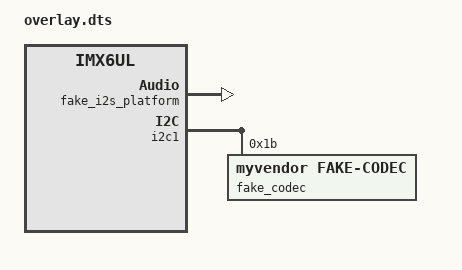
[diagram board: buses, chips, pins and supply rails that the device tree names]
// SPDX-License-Identifier: GPL-2.0
/*
 * Device Tree Overlay for Fake Audio Driver
 * Reference implementation showing required nodes
 */

/dts-v1/;
/plugin/;

/ {
	compatible = "fsl,imx6ul-14x14-evk", "fsl,imx6ul";

	fragment@0 {
		target-path = "/soc";
		__overlay__ {
			fake_cpu_dai: fake_cpu_dai {
				compatible = "myvendor,fake-cpu-dai";
				#sound-dai-cells = <0>;
			};

			fake_i2s_platform: fake_i2s_platform {
				compatible = "myvendor,fake-i2s-platform";
				#sound-dai-cells = <0>;
			};
		};
	};

	fragment@1 {
		target-path = "/";
		__overlay__ {
			fake-audio-card {
				compatible = "myvendor,fake-audio-card";
				audio-cpu = <&fake_cpu_dai>;
				audio-codec = <&fake_codec>;
				audio-platform = <&fake_i2s_platform>;
			};
		};
	};

	fragment@2 {
		target = <&i2c1>;
		__overlay__ {
			#address-cells = <1>;
			#size-cells = <0>;

			fake_codec: fake_codec@1b {
				compatible = "myvendor,fake-codec";
				reg = <0x1b>;
			};
		};
	};
};
